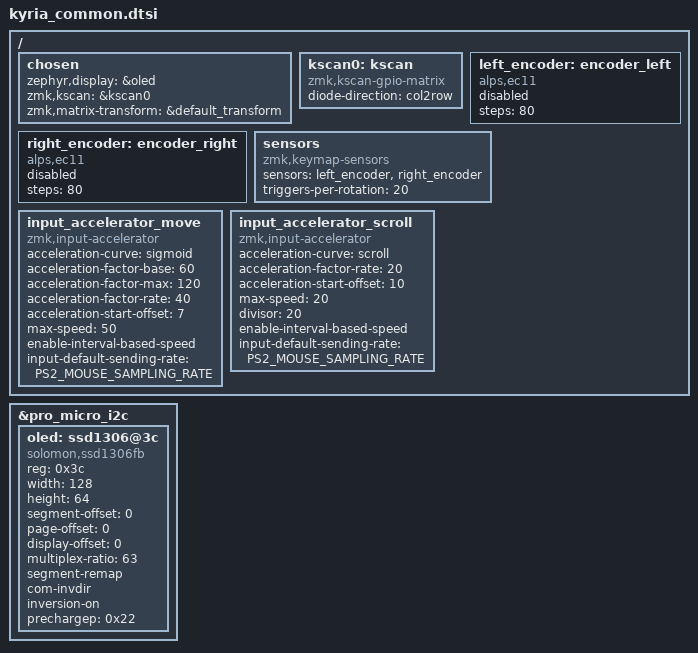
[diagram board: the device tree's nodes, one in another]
/*
 * Copyright (c) 2022 The ZMK Contributors
 *
 * SPDX-License-Identifier: MIT
 */

#include <dt-bindings/zmk/matrix_transform.h>

#define PS2_MOUSE_SAMPLING_RATE 100

/ {
    chosen {
        zephyr,display = &oled;
        zmk,kscan = &kscan0;
        zmk,matrix-transform = &default_transform;
    };

    kscan0: kscan {
        compatible = "zmk,kscan-gpio-matrix";

        diode-direction = "col2row";
    };

    left_encoder: encoder_left {
        compatible = "alps,ec11";
        steps = <80>;
        status = "disabled";
    };

    right_encoder: encoder_right {
        compatible = "alps,ec11";
        steps = <80>;
        status = "disabled";
    };

    sensors: sensors {
        compatible = "zmk,keymap-sensors";
        sensors = <&left_encoder &right_encoder>;
        triggers-per-rotation = <20>;
    };

    // TODO: RGB node(s)

    input_accelerator_move: input_accelerator_move {
        status = "okay";
        compatible = "zmk,input-accelerator";

        acceleration-curve = "sigmoid";
        acceleration-factor-base = <60>;
        acceleration-factor-max = <120>;
        acceleration-factor-rate = <40>;
        acceleration-start-offset = <7>;
        max-speed = <50>;

        enable-interval-based-speed;
        input-default-sending-rate = <PS2_MOUSE_SAMPLING_RATE>;
    };

    input_accelerator_scroll: input_accelerator_scroll {
        status = "okay";
        compatible = "zmk,input-accelerator";

        acceleration-curve = "scroll";
        acceleration-factor-rate = <20>;
        acceleration-start-offset = <10>;
        max-speed = <20>;
        divisor = <20>;

        enable-interval-based-speed;
        input-default-sending-rate = <PS2_MOUSE_SAMPLING_RATE>;
    };
};

&pro_micro_i2c {
    status = "okay";

    oled: ssd1306@3c {
        compatible = "solomon,ssd1306fb";
        reg = <0x3c>;
        width = <128>;
        height = <64>;
        segment-offset = <0>;
        page-offset = <0>;
        display-offset = <0>;
        multiplex-ratio = <63>;
        segment-remap;
        com-invdir;
        inversion-on;
        prechargep = <0x22>;
    };
};
